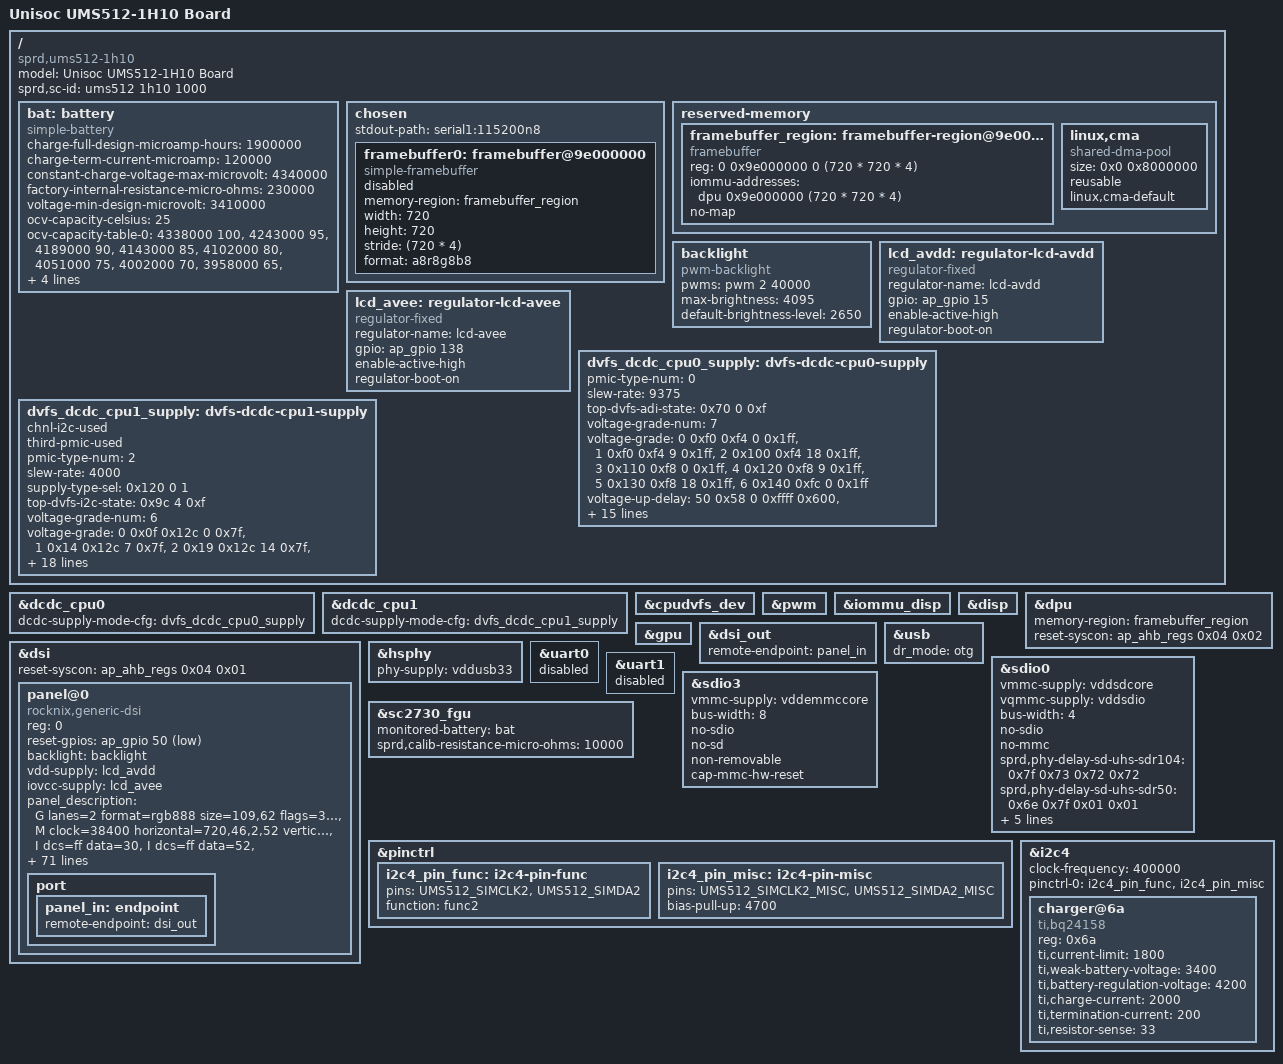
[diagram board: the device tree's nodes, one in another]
// SPDX-License-Identifier: (GPL-2.0 OR MIT)
/*
 * Unisoc UMS512-1h10 boards DTS file
 *
 * Copyright (C) 2021, Unisoc Inc.
 */

/dts-v1/;

#include "ums512.dtsi"
#include "sc2730.dtsi"

/ {
	model = "Unisoc UMS512-1H10 Board";
	compatible = "sprd,ums512-1h10", "sprd,ums512";
	sprd,sc-id = "ums512 1h10 1000";

	/*
	 * Battery profile for the RG Rotate cell. Values transcribed from the
	 * stock dtbo overlay (device/stock/dtbo_decompiled/dtbo_overlay_1.dts,
	 * the authoritative source for this SKU). Consumed by the SC2730 fuel
	 * gauge (sc2730_fgu) via monitored-battery.
	 */
	bat: battery {
		compatible = "simple-battery";
		charge-full-design-microamp-hours = <1900000>;
		charge-term-current-microamp = <120000>;
		constant-charge-voltage-max-microvolt = <4340000>;
		factory-internal-resistance-micro-ohms = <230000>;
		voltage-min-design-microvolt = <3410000>;
		ocv-capacity-celsius = <25>;
		ocv-capacity-table-0 = <4338000 100>, <4243000 95>,
			<4189000 90>, <4143000 85>, <4102000 80>,
			<4051000 75>, <4002000 70>, <3958000 65>,
			<3901000 60>, <3840000 55>, <3784000 50>,
			<3742000 45>, <3703000 40>, <3673000 35>,
			<3656000 30>, <3622000 25>, <3595000 20>,
			<3558000 15>, <3523000 10>, <3490000 5>,
			<3412000 0>;
	};

	chosen {
		#address-cells = <2>;
		#size-cells = <2>;
		stdout-path = "serial1:115200n8";

		framebuffer0: framebuffer@9e000000 {
			compatible = "simple-framebuffer";
			memory-region = <&framebuffer_region>;
			width = <720>;
			height = <720>;
			stride = <(720 * 4)>;
			format = "a8r8g8b8";

			status = "disabled";
		};
	};

	reserved-memory {
		#address-cells = <2>;
		#size-cells = <2>;
		ranges;

		framebuffer_region: framebuffer-region@9e000000 {
			compatible = "framebuffer";
			reg = <0 0x9e000000 0 (720 * 720 * 4)>;
			iommu-addresses = <&dpu 0x9e000000 (720 * 720 * 4)>;
			no-map;
		};

		linux,cma {
			compatible = "shared-dma-pool";
			size = <0x0 0x8000000>;
			reusable;
			linux,cma-default;
		};
	};

	backlight: backlight {
		compatible = "pwm-backlight";
		pwms = <&pwm 2 40000>;
		max-brightness = <4095>;
		default-brightness-level = <2650>;
	};

	lcd_avdd: regulator-lcd-avdd {
		compatible = "regulator-fixed";
		regulator-name = "lcd-avdd";
		gpio = <&ap_gpio 15 GPIO_ACTIVE_HIGH>;
		enable-active-high;
		regulator-boot-on;
	};

	lcd_avee: regulator-lcd-avee {
		compatible = "regulator-fixed";
		regulator-name = "lcd-avee";
		gpio = <&ap_gpio 138 GPIO_ACTIVE_HIGH>;
		enable-active-high;
		regulator-boot-on;
	};

	/*
	 * CPU register-level DVFS supply config (real ums512-1h10 silicon
	 * values from vendor/linux-kernel-4-14-sprd). CPU0 (little) drives its
	 * DCDC via the SoC top-dvfs ADI path; CPU1 (big) drives the third PMIC
	 * via the SoC top-dvfs hardware i2c master (chnl-in-i2c = 1) - no Linux
	 * i2c regulator needed, matching the stock DTB (aon_i2c0 left disabled).
	 */
	dvfs_dcdc_cpu0_supply: dvfs-dcdc-cpu0-supply {
		pmic-type-num = <0>;
		slew-rate = <9375>; /* 9375uV/us */
		top-dvfs-adi-state = <0x70 0 0xf>;
		voltage-grade-num = <7>;
		voltage-grade = <0 0xf0 0xf4 0 0x1ff>,
			<1 0xf0 0xf4 9 0x1ff>,
			<2 0x100 0xf4 18 0x1ff>,
			<3 0x110 0xf8 0 0x1ff>,
			<4 0x120 0xf8 9 0x1ff>,
			<5 0x130 0xf8 18 0x1ff>,
			<6 0x140 0xfc 0 0x1ff>;
		voltage-up-delay = <50 0x58 0 0xffff 0x600>,
			<100 0x58 16 0xffff 0xa00>,
			<150 0x54 0 0xffff 0xf00>,
			<200 0x54 16 0xffff 0x1400>,
			<250 0x50 0 0xffff 0x1900>,
			<300 0x50 16 0xffff 0x1e00>,
			<350 0x110 0 0xffff 0x2300>;
		voltage-down-delay = <50 0x64 0 0xffff 0x600>,
			<100 0x64 16 0xffff 0xa00>,
			<150 0x60 0 0xffff 0xf00>,
			<200 0x60 16 0xffff 0x1400>,
			<250 0x5c 0 0xffff 0x1900>,
			<300 0x5c 16 0xffff 0x1e00>,
			<350 0x114 0 0xffff 0x2300>;
		tuning-latency-us = <0>;
		chnl-in-i2c = <0>;
	};

	dvfs_dcdc_cpu1_supply: dvfs-dcdc-cpu1-supply {
		chnl-i2c-used;
		third-pmic-used;
		pmic-type-num = <2>;
		slew-rate = <4000>; /* 4000uV/us */
		supply-type-sel = <0x120 0 1>;
		top-dvfs-i2c-state = <0x9c 4 0xf>;
		voltage-grade-num = <6>;
		voltage-grade = <0 0x0f 0x12c 0 0x7f>,
			<1 0x14 0x12c 7 0x7f>,
			<2 0x19 0x12c 14 0x7f>,
			<3 0x1e 0x12c 21 0x7f>,
			<4 0x23 0x130 0 0x7f>,
			<5 0x28 0x130 7 0x7f>;
		voltage-up-delay = <50 0x84 0 0xffff 0x1600>,
			<100 0x84 16 0xffff 0x1a00>,
			<150 0x80 0 0xffff 0x1f00>,
			<200 0x80 16 0xffff 0x2400>,
			<250 0x7c 0 0xffff 0x2900>,
			<300 0x7c 16 0xffff 0x2e00>,
			<350 0x118 0 0xffff 0x3300>;
		voltage-down-delay = <50 0x90 0 0xffff 0x600>,
			<100 0x90 16 0xffff 0xa00>,
			<150 0x8c 0 0xffff 0xf00>,
			<200 0x8c 16 0xffff 0x1400>,
			<250 0x88 0 0xffff 0x1900>,
			<300 0x88 16 0xffff 0x1e00>,
			<350 0x11c 0 0xffff 0x2300>;
		tuning-latency-us = <0>;
		chnl-in-i2c = <1>;
	};
};

&dcdc_cpu0 {
	dcdc-supply-mode-cfg = <&dvfs_dcdc_cpu0_supply>;
};

&dcdc_cpu1 {
	dcdc-supply-mode-cfg = <&dvfs_dcdc_cpu1_supply>;
};

&cpudvfs_dev {
	status = "okay";
};

&pwm {
	status = "okay";
};

&iommu_disp {
	status = "okay";
};

&disp {
	status = "okay";
};

&dpu {
	status = "okay";
	memory-region = <&framebuffer_region>;
	reset-syscon = <&ap_ahb_regs 0x04 0x02>;
};

&gpu {
	status = "okay";
};

&dsi {
	status = "okay";
	reset-syscon = <&ap_ahb_regs 0x04 0x01>;

	#address-cells = <1>;
	#size-cells = <0>;

	panel@0 {
		compatible = "rocknix,generic-dsi";
		reg = <0>;
		reset-gpios = <&ap_gpio 50 GPIO_ACTIVE_LOW>;
		backlight = <&backlight>;
		vdd-supply = <&lcd_avdd>;
		iovcc-supply = <&lcd_avee>;

		panel_description =
			"G lanes=2 format=rgb888 size=109,62 flags=3 hs_rate=551488000 lp_rate=20000000 delays=5,50,120,100,50",
			"M clock=38400 horizontal=720,46,2,52 vertical=720,30,2,25 default=1",
			"I dcs=ff data=30",
			"I dcs=ff data=52",
			"I dcs=ff data=01",
			"I dcs=e3 data=00",
			"I dcs=25 data=0a",
			"I dcs=28 data=5f",
			"I dcs=29 data=c2",
			"I dcs=2a data=cf",
			"I dcs=30 data=58",
			"I dcs=37 data=9c",
			"I dcs=38 data=a7",
			"I dcs=39 data=1f",
			"I dcs=44 data=00",
			"I dcs=49 data=3c",
			"I dcs=59 data=fe",
			"I dcs=5c data=00",
			"I dcs=80 data=20",
			"I dcs=91 data=77",
			"I dcs=92 data=77",
			"I dcs=a0 data=55",
			"I dcs=a1 data=50",
			"I dcs=a3 data=58",
			"I dcs=a4 data=9c",
			"I dcs=a7 data=02",
			"I dcs=a8 data=01",
			"I dcs=a9 data=01",
			"I dcs=aa data=fc",
			"I dcs=ab data=28",
			"I dcs=ac data=06",
			"I dcs=ad data=06",
			"I dcs=ae data=06",
			"I dcs=af data=03",
			"I dcs=b0 data=08",
			"I dcs=b1 data=26",
			"I dcs=b2 data=28",
			"I dcs=b3 data=28",
			"I dcs=b4 data=03",
			"I dcs=b5 data=08",
			"I dcs=b6 data=26",
			"I dcs=b7 data=08",
			"I dcs=b8 data=26",
			"I dcs=c0 data=00",
			"I dcs=c1 data=00",
			"I dcs=c2 data=00",
			"I dcs=c3 data=0f",
			"I dcs=ff data=30",
			"I dcs=ff data=52",
			"I dcs=ff data=02",
			"I dcs=b0 data=00",
			"I dcs=b1 data=0f",
			"I dcs=b2 data=12",
			"I dcs=b3 data=32",
			"I dcs=b4 data=24",
			"I dcs=b5 data=3f",
			"I dcs=b6 data=25",
			"I dcs=b7 data=3f",
			"I dcs=b8 data=0e",
			"I dcs=b9 data=06",
			"I dcs=ba data=11",
			"I dcs=bb data=10",
			"I dcs=bc data=10",
			"I dcs=bd data=13",
			"I dcs=be data=1b",
			"I dcs=bf data=10",
			"I dcs=c0 data=17",
			"I dcs=c1 data=08",
			"I dcs=d0 data=00",
			"I dcs=d1 data=0d",
			"I dcs=d2 data=12",
			"I dcs=d3 data=2a",
			"I dcs=d4 data=2e",
			"I dcs=d5 data=3f",
			"I dcs=d6 data=29",
			"I dcs=d7 data=43",
			"I dcs=d8 data=10",
			"I dcs=d9 data=08",
			"I dcs=da data=13",
			"I dcs=db data=10",
			"I dcs=dc data=12",
			"I dcs=dd data=13",
			"I dcs=de data=1f",
			"I dcs=df data=1a",
			"I dcs=e0 data=1f",
			"I dcs=e1 data=0a",
			"I dcs=ff data=30",
			"I dcs=ff data=52",
			"I dcs=ff data=03",
			"I dcs=04 data=51",
			"I dcs=05 data=c0",
			"I dcs=06 data=c0",
			"I dcs=08 data=86",
			"I dcs=09 data=87",
			"I dcs=0a data=84",
			"I dcs=0b data=85",
			"I dcs=28 data=33",
			"I dcs=29 data=33",
			"I dcs=2a data=eb",
			"I dcs=2b data=ea",
			"I dcs=2c data=ed",
			"I dcs=2d data=ec",
			"I dcs=34 data=81",
			"I dcs=35 data=53",
			"I dcs=37 data=23",
			"I dcs=40 data=84",
			"I dcs=41 data=85",
			"I dcs=42 data=82",
			"I dcs=43 data=83",
			"I dcs=44 data=33",
			"I dcs=45 data=ea",
			"I dcs=46 data=e9",
			"I dcs=47 data=33",
			"I dcs=48 data=ec",
			"I dcs=49 data=eb",
			"I dcs=50 data=80",
			"I dcs=51 data=81",
			"I dcs=52 data=02",
			"I dcs=53 data=01",
			"I dcs=54 data=33",
			"I dcs=55 data=ee",
			"I dcs=56 data=ed",
			"I dcs=57 data=33",
			"I dcs=58 data=f0",
			"I dcs=59 data=ef",
			"I dcs=80 data=00",
			"I dcs=81 data=01",
			"I dcs=82 data=06",
			"I dcs=83 data=07",
			"I dcs=84 data=04",
			"I dcs=85 data=05",
			"I dcs=92 data=03",
			"I dcs=93 data=02",
			"I dcs=96 data=00",
			"I dcs=97 data=01",
			"I dcs=98 data=06",
			"I dcs=99 data=07",
			"I dcs=9a data=04",
			"I dcs=9b data=05",
			"I dcs=a8 data=03",
			"I dcs=a9 data=02",
			"I dcs=ff data=30",
			"I dcs=ff data=52",
			"I dcs=ff data=00",
			"I dcs=36 data=01",
			"I dcs=53 data=2c";

		port {
			panel_in: endpoint {
				remote-endpoint = <&dsi_out>;
			};
		};
	};
};

&dsi_out {
	remote-endpoint = <&panel_in>;
};

&hsphy {
	status = "okay";

	phy-supply = <&vddusb33>;
};

&usb {
	status = "okay";
	/*
	 * MUST stay "otg". The sprd musb glue only registers the usb_role_switch
	 * (/sys/class/usb_role/*) when port_mode == MUSB_OTG, and this board has
	 * no extcon/VBUS session edge -- the PHY force-asserts VBUS. The gadget
	 * session + D+ pullup are only asserted via sprd_otg_switch_set(DEVICE),
	 * which the initramfs init triggers by writing "device" to the role
	 * sysfs. Setting dr_mode="peripheral" removes the role switch, so the
	 * init dance no-ops and the gadget never asserts its session -> the host
	 * sees a connect but EP0 is dead (descriptor read error -71). See
	 * drivers/usb/musb/sprd.c and src/initramfs/init.
	 */
	dr_mode = "otg";
};

&uart0 {
	status = "disabled";
};

&uart1 {
	status = "disabled";
};

/* SD card */
&sdio0 {
	/*
	 * Claim the SD core/IO supplies so the regulator framework keeps them
	 * powered without relying on regulator_ignore_unused (mirrors the
	 * working ums512-infinix-x6816d board).
	 */
	vmmc-supply = <&vddsdcore>;
	vqmmc-supply = <&vddsdio>;
	bus-width = <4>;
	no-sdio;
	no-mmc;
	sprd,phy-delay-sd-uhs-sdr104 = <0x7f 0x73 0x72 0x72>;
	sprd,phy-delay-sd-uhs-sdr50 = <0x6e 0x7f 0x01 0x01>;
	sprd,phy-delay-sd-highspeed = <0x7f 0x1a 0x9a 0x9a>;
	sprd,phy-delay-legacy = <0x7f 0x1a 0x9a 0x9a>;
	sd-uhs-sdr104;
	sd-uhs-sdr50;
};

/* EMMC storage */
&sdio3 {
	status = "okay";
	/*
	 * Claim the eMMC core supply so it stays powered without
	 * regulator_ignore_unused (mirrors ums512-infinix-x6816d). This is the
	 * regulator that, when dropped, kills eMMC and stops userland binaries
	 * from loading mid-session.
	 */
	vmmc-supply = <&vddemmccore>;
	bus-width = <8>;
	no-sdio;
	no-sd;
	non-removable;
	cap-mmc-hw-reset;
};

/* SC2730 fuel gauge — battery voltage / capacity reporting */
&sc2730_fgu {
	status = "okay";
	monitored-battery = <&bat>;
	sprd,calib-resistance-micro-ohms = <10000>;
};

/*
 * Battery charger. Stock uses an AW32257 (Awinic) at i2c4 addr 0x6a, which is a
 * register-level clone of the TI bq24157/bq24158. Probe-test it with the
 * mainline bq2415x driver. Values transcribed from the stock dtbo overlay
 * (dtbo_overlay_1.dts charger@6a), converted to the bq2415x binding units
 * (mA / mV; stock used vendor units of uA for currents, mV for voltages):
 *   current-limit 2000000uA->1800mA (bq2415x max), charge 2000000uA->2000mA,
 *   weak-batt 3400mV, batt-reg 4200mV, resistor-sense 33mOhm (0x21).
 * Termination set to a sane 200mA (stock's 2000mA looks like a vendor copy).
 */
/*
 * i2c4 SCL/SDA are routed onto the SIMCLK2 / SIMDA2 pads at AF1 with
 * internal pull-ups. Source: vendor u-boot board pinmap
 * (vendor/u-boot-unisoc-bsp/board/spreadtrum/ums512_1h10/pinmap.c: SIMCLK2 =>
 * I2C4_SCL, SIMDA2 => I2C4_SDA, both BITS_PIN_AF(1) + WPU). UMS512 has no
 * dedicated SCL4/SDA4 pads, and the stock pinmux lived in the (neutralized)
 * dtbo, so it must be set here or the bus never toggles (all xfers -ETIMEDOUT).
 *
 * NB: the sprd DT function naming is 1-indexed vs the hardware AF number:
 * sprd_pmx_set_mux() maps "func1"->AF0, "func2"->AF1, ... (PIN_FUNC_1 clears
 * the bits). I2C4 is AF1, so the correct string is "func2", NOT "func1".
 */
&pinctrl {
	i2c4_pin_func: i2c4-pin-func {
		pins = "UMS512_SIMCLK2", "UMS512_SIMDA2";
		function = "func2";
	};

	i2c4_pin_misc: i2c4-pin-misc {
		pins = "UMS512_SIMCLK2_MISC", "UMS512_SIMDA2_MISC";
		/* 4700 => WPUS|WPU (bit12|bit7), matching the u-boot pinmap; 20000
		 * would set WPU only. Stronger pull for the open-drain i2c lines. */
		bias-pull-up = <4700>;
	};
};

&i2c4 {
	status = "okay";
	clock-frequency = <400000>;
	pinctrl-names = "default";
	pinctrl-0 = <&i2c4_pin_func &i2c4_pin_misc>;
	#address-cells = <1>;
	#size-cells = <0>;

	charger@6a {
		compatible = "ti,bq24158";
		reg = <0x6a>;
		ti,current-limit = <1800>;
		ti,weak-battery-voltage = <3400>;
		ti,battery-regulation-voltage = <4200>;
		ti,charge-current = <2000>;
		ti,termination-current = <200>;
		ti,resistor-sense = <33>;
	};
};
